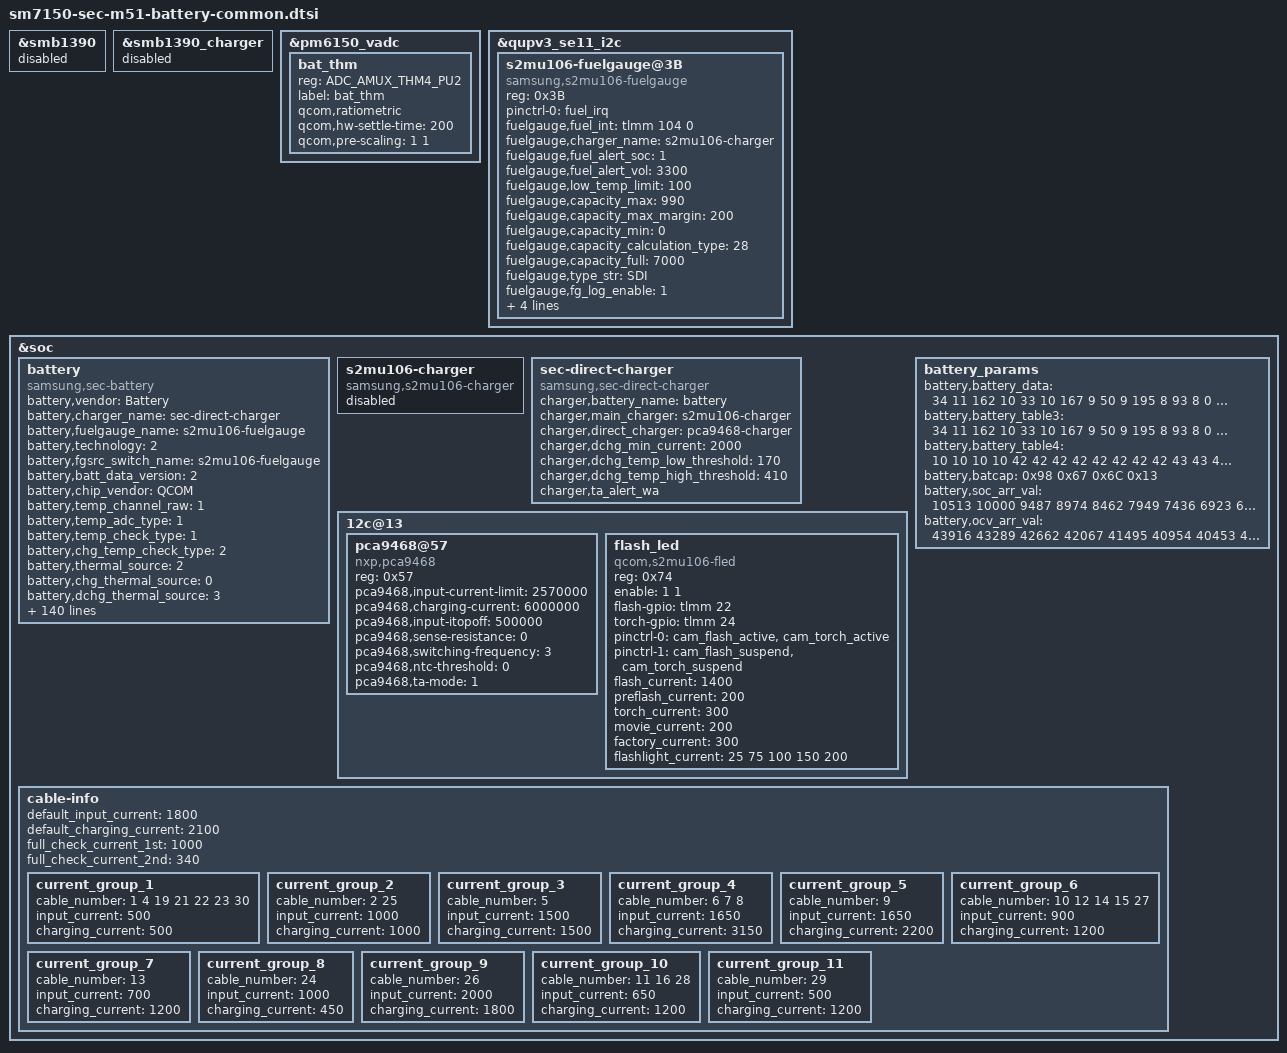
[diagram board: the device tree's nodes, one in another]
/* Copyright (c) 2019, The Linux Foundation. All rights reserved.
 *
 * This program is free software; you can redistribute it and/or modify
 * it under the terms of the GNU General Public License version 2 and
 * only version 2 as published by the Free Software Foundation.
 *
 * This program is distributed in the hope that it will be useful,
 * but WITHOUT ANY WARRANTY; without even the implied warranty of
 * MERCHANTABILITY or FITNESS FOR A PARTICULAR PURPOSE.  See the
 * GNU General Public License for more details.
 */

&smb1390 {
    status = "disabled";
};

&smb1390_charger {
    status = "disabled";
};

&pm6150_vadc {
	bat_thm {
		reg = <ADC_AMUX_THM4_PU2>;
		label = "bat_thm";
		qcom,ratiometric;
		qcom,hw-settle-time = <200>;
		qcom,pre-scaling = <1 1>;
	};
};

&qupv3_se11_i2c{
		status = "ok";

		s2mu106-fuelgauge@3B{
			compatible = "samsung,s2mu106-fuelgauge";
			reg = <0x3B>;
			pinctrl-names = "default";
			pinctrl-0 = <&fuel_irq>;
			fuelgauge,fuel_int = <&tlmm 104 0>;
			fuelgauge,charger_name = "s2mu106-charger";
			fuelgauge,fuel_alert_soc = <1>;
			fuelgauge,fuel_alert_vol = <3300>;
			fuelgauge,low_temp_limit = <100>;
			fuelgauge,capacity_max = <990>;
			fuelgauge,capacity_max_margin = <200>;
			fuelgauge,capacity_min = <0>;
			fuelgauge,capacity_calculation_type = <28>;
			fuelgauge,capacity_full = <7000>;
			fuelgauge,type_str = "SDI";
			fuelgauge,fg_log_enable = <1>;
			fuelgauge,low_voltage_limit = <3450>;
			fuelgauge,low_voltage_limit_lowtemp = <3000>;
			fuelgauge,i_socr_coeff = <80>;
			fuelgauge,low_t_compen_coeff = <180>;
		};
	};

&soc {
	battery {
		status = "okay";
		compatible = "samsung,sec-battery";
		pinctrl-names = "default";

		battery,vendor = "Battery";
		battery,charger_name = "sec-direct-charger";
		battery,fuelgauge_name = "s2mu106-fuelgauge";
		battery,technology = <2>; /* POWER_SUPPLY_TECHNOLOGY_LION */
		battery,fgsrc_switch_name = "s2mu106-fuelgauge"; /* Fuelgauge voltage source */

		battery,batt_data_version = <2>;

		battery,chip_vendor = "QCOM";
		battery,temp_channel_raw= <1>; /* BATTERY_TEMP_CHANNEL_RAW */
		battery,temp_adc_type = <1>; /* SEC_BATTERY_ADC_TYPE_AP */

		battery,temp_check_type = <1>; /* SEC_BATTERY_TEMP_CHECK_ADC */
		battery,chg_temp_check_type = <2>; /* SEC_BATTERY_TEMP_CHECK_TEMP*/

		battery,thermal_source = <2>; /* SEC_BATTERY_THERMAL_SOURCE_ADC */
		battery,chg_thermal_source = <0>; /* SEC_CHARGER_THERMAL_SOURCE_FG */

		battery,dchg_thermal_source = <3>; /* SEC_BATTERY_THERMAL_SOURCE_CHG_ADC */
		battery,polling_time = <10 30 30 30 3600>;
		

		battery,temp_table_adc = <
					1998 2411 2824 3310 3882 4543 5384 6302 7337 8485
					9728 11153 12702 14344 16061 17803 19417 20947 22363 23642
					24732 25654 26427
					>;
		battery,temp_table_data = <
					900 850 800 750 700 650 600 550	500 450
					400 350 300	250 200 150 100 50 0 (-50)
					(-100) (-150) (-200)
					>;

		battery,inbat_voltage = <1>;

		battery,inbat_voltage_table_adc = <
					2820 2795 2767 2737 2706 2686 2659 2630 2602 2574
					2544 2514 2484 2456 2432 2405 2379 2351 2320 2292
					2265 2236 2207
					>;
		battery,inbat_voltage_table_data = <
					4400 4350 4300 4250 4200 4150 4100 4050 4000 3950
					3900 3850 3800 3750 3700 3650 3600 3550 3500 3450
					3400 3350 3300
					>;
		battery,dchg_temp_table_adc = <99705 125511 151317 182988 211140 258060 308499 365976 428145 498525
					575943 663918 757758 859809 968898 1080333 1182384 1279743 1368891 1452174 1523727 1583550 1635162>;
		battery,dchg_temp_table_data = <900 850 800 750 700 650 600 550 500 450
					400 350 300 250 200 150 100 50 0 (-50) (-100) (-150) (-200)>;

		battery,adc_check_count = <5>;

		battery,cable_check_type = <4>; /* SEC_BATTERY_CABLE_CHECK_PSY */
		battery,cable_source_type = <1>; /* SEC_BATTERY_CABLE_SOURCE_EXTERNAL */
		battery,polling_type = <1>; /* SEC_BATTERY_MONITOR_ALARM */
		battery,monitor_initial_count = <0>;

		battery,pre_afc_input_current = <500>;
		battery,prepare_afc_delay = <0>;

		battery,battery_check_type = <0>; /* SEC_BATTERY_CHECK_NONE */
		battery,check_count = <0>;

		battery,ovp_uvlo_check_type = <3>; /* SEC_BATTERY_OVP_UVLO_CHGPOLLING */

		battery,temp_check_count = <1>;
		battery,temp_highlimit_threshold_event = <700>;
		battery,temp_highlimit_recovery_event = <680>;
		battery,temp_high_threshold_event = <500>;
		battery,temp_high_recovery_event = <480>;
		battery,temp_low_threshold_event = <0>;
		battery,temp_low_recovery_event = <20>;
		battery,temp_highlimit_threshold_normal = <700>;
		battery,temp_highlimit_recovery_normal = <680>;
		battery,temp_high_threshold_normal = <500>;
		battery,temp_high_recovery_normal = <480>;
		battery,temp_low_threshold_normal = <0>;
		battery,temp_low_recovery_normal = <20>;
		battery,temp_highlimit_threshold_lpm = <800>;
		battery,temp_highlimit_recovery_lpm = <750>;
		battery,temp_high_threshold_lpm = <500>;
		battery,temp_high_recovery_lpm = <480>;
		battery,temp_low_threshold_lpm = <0>;
		battery,temp_low_recovery_lpm = <20>;
		battery,wpc_high_threshold_normal = <450>;
		battery,wpc_high_recovery_normal = <400>;
		battery,wpc_low_threshold_normal = <0>;
		battery,wpc_low_recovery_normal = <50>;

		battery,full_check_type = <2>; /* SEC_BATTERY_FULLCHARGED_FG_CURRENT */
		battery,full_check_type_2nd = <2>; /* SEC_BATTERY_FULLCHARGED_FG_CURRENT */
		battery,full_check_count = <1>;
		battery,chg_gpio_full_check = <0>;
		battery,chg_polarity_full_check = <1>;

		battery,chg_heating_prevention_method = <1>; /* SEC_BATTERY_BY_CHANGING_CURRENT */
		battery,chg_high_temp = <490>;
		battery,chg_high_temp_recovery = <450>;
		battery,chg_input_limit_current = <1000>;
		battery,chg_charging_limit_current = <1800>;
		battery,dchg_input_limit_current = <1000>;
		battery,dchg_charging_limit_current = <2000>;

		battery,mix_high_temp = <420>;
		battery,mix_high_chg_temp = <500>;
		battery,mix_high_temp_recovery = <390>;

		/* SEC_BATTERY_FULL_CONDITION_SOC |
		 * SEC_BATTERY_FULL_CONDITION_NOTIMEFULL |
		 * SEC_BATTERY_FULL_CONDITION_VCELL
		 */
		battery,full_condition_type = <13>;
		battery,full_condition_soc = <93>;
		battery,full_condition_vcell = <4250>;

		battery,recharge_check_count = <1>;
		battery,recharge_condition_type = <4>; /* SEC_BATTERY_RECHARGE_CONDITION_VCELL */
		battery,recharge_condition_soc = <98>;
		battery,recharge_condition_vcell = <4310>;

		battery,charging_total_time = <14400>;
		battery,hv_charging_total_time = <10800>;
		battery,normal_charging_total_time = <18000>;
		battery,usb_charging_total_time = <36000>;
		battery,recharging_total_time = <5400>;
		battery,charging_reset_time = <0>;

		battery,chg_float_voltage = <4380>;

		battery,swelling_high_temp_block = <410>;
		battery,swelling_high_temp_recov = <390>;
		battery,swelling_wc_high_temp_recov = <390>;
		battery,swelling_low_temp_block_1st = <150>;
		battery,swelling_low_temp_recov_1st = <170>;
		battery,swelling_low_temp_block_2nd = <50>;
		battery,swelling_low_temp_recov_2nd = <70>;

		battery,swelling_low_temp_current = <1750>;
		battery,swelling_low_temp_current_2nd = <680>;
		battery,swelling_low_temp_topoff = <340>;
		battery,swelling_high_temp_current = <2600>;
		battery,swelling_high_temp_topoff = <340>;
		battery,swelling_wc_high_temp_current = <750>;	/* 0.3C */
		battery,swelling_wc_low_temp_current = <750>;	/* 0.3C */

		battery,swelling_drop_float_voltage = <4150>;
		battery,swelling_high_rechg_voltage = <4000>;
		battery,swelling_low_rechg_voltage = <4230>;

		battery,dchg_high_temp = <470>;
		battery,dchg_high_temp_recovery = <430>;

		battery,siop_event_check_type = <1>;
		battery,siop_call_cv_current = <330>;
		battery,siop_call_cc_current = <330>;

		battery,siop_input_limit_current = <1200>;
		battery,siop_charging_limit_current = <1000>;
		battery,siop_hv_input_limit_current = <700>;
		battery,siop_hv_charging_limit_current = <1000>;
		battery,input_current_by_siop_20 = <400>;

		battery,rp_current_rp1 = <500>;
		battery,rp_current_rp2 = <1500>;
		battery,rp_current_rp3 = <3000>;
		battery,rp_current_rdu_rp3 = <2100>;
		battery,rp_current_abnormal_rp3 = <1800>;

		battery,pd_charging_charge_power = <15000>;
		battery,max_charging_current = <3150>;
		battery,battery_full_capacity = <7000>;

		battery,ttf_hv_charge_current = <2550>;
		battery,ttf_dc25_charge_current = <3300>;

		battery,ttf_capacity = <5650>;
		battery,cv_data = <
					3435	832	1800
					3365	837	1770
					3298	841	1740
					3177	850	1680
					3042	858	1620
					2958	864	1560
					2834	871	1500
					2751	879	1440
					2644	886	1380
					2550	891	1320
					2467	898	1260
					2389	905	1200
					2294	910	1140
					2219	916	1080
					2124	921	1020
					2049	926	960
					1961	931	900
					1927	938	840
					1838	942	780
					1756	945	720
					1725	949	660
					1648	952	600
					1577	959	540
					1541	966	480
					1498	972	420
					1396	976	360
					1376	981	300
					1347	986	240
					1269	990	180
					1242	993	120
					1211	996	60
					1170	1000	0
					>;

		/* cycle, chg_float_voltage, recharge_condition_vcell, full_condition_vcell, full_condition_soc, step charging condition */
		battery,age_data = <0 4380 4310 4280 93
			300 4360 4290 4260 92
			400 4340 4270 4240 91
			700 4320 4250 4220 90
			1000 4270 4200 4170 89>;

		/* step charging option */
		battery,step_charging_type = <0>;

		/* direct step charging option */
		battery,dc_step_chg_type = <0xE9>;
		battery,dc_step_chg_charge_power = <22000>;
		battery,dc_step_chg_step = <3>;
		battery,dc_step_chg_cond_vol = <4090 4190 4350>; /* STEP_CHARGING_CONDITION_VOLTAGE */
		battery,dc_step_chg_cond_iin = <1950 1575 0>; /* STEP_CHARGING_CONDITION_INPUT_CURRENT */
		battery,dc_step_chg_iin_check_cnt = <3>;
		battery,dc_step_chg_cond_soc = <9 48 100>; /* STEP_CHARGING_CONDITION_SOC */
		battery,dc_step_chg_val_vfloat = <4075 4250 4380>; /* STEP_CHARGING_CONDITION_FLOAT_VOLTAGE */
		battery,dc_step_chg_val_iout = <5300 3900 3450>;

		battery,max_input_voltage = <9000>; /* mV */
		battery,max_input_current = <3000>; /* mA */

		battery,standard_curr = <3450>;
		battery,expired_time = <12600>; /* (148 + 60) ~ 210 minutes */
		battery,recharging_expired_time = <5400>;

		battery,cisd_alg_index = <7>;

		battery,cisd_max_voltage_thr = <5000>; /* battery ovp detection voltage */

		io-channels = <&pm6150_vadc ADC_AMUX_THM4_PU2>;
		io-channel-names = "adc-temp";

		battery,recovery_cable;
		battery,lowtemp_support_full_volt;
		battery,enable_water_resistance;
		battery,ta_alert_wa;
	};


	s2mu106-charger {
		status = "disable";
		compatible = "samsung,s2mu106-charger";
	};

	sec-direct-charger {
			status = "okay";
			compatible = "samsung,sec-direct-charger";

			charger,battery_name = "battery";
			charger,main_charger = "s2mu106-charger";
			charger,direct_charger = "pca9468-charger";

			charger,dchg_min_current = <2000>;
			charger,dchg_temp_low_threshold = <170>;
			charger,dchg_temp_high_threshold = <410>;
			charger,ta_alert_wa;
		};

	12c@13 {
		pca9468@57 {
			compatible = "nxp,pca9468";
			reg = <0x57>;
			pca9468,input-current-limit = <2570000>; /* 2.57A */
			pca9468,charging-current = <6000000>; /* 6A */
			pca9468,input-itopoff = <500000>; /* 500mA */
			pca9468,sense-resistance = <0>; /* 5mOhm */
			pca9468,switching-frequency = <3>; /* 980KHz */
			pca9468,ntc-threshold = <0>; /* disable */
			pca9468,ta-mode = <1>; /* 2:1 charging mode */
		};

		flash_led {
			reg = <0x74>;
			compatible = "qcom,s2mu106-fled";
			enable = <1 1>;
			flash-gpio = <&tlmm 22 0>;
			torch-gpio = <&tlmm 24 0>;
			pinctrl-names = "fled_default", "fled_suspend";
			pinctrl-0 = <&cam_flash_active &cam_torch_active>;
			pinctrl-1 = <&cam_flash_suspend &cam_torch_suspend>;
			flash_current = <1400>;
			preflash_current = <200>;
			torch_current = <300>;
			movie_current = <200>;
			factory_current = <300>;
			flashlight_current = <25 75 100 150 200>;
			status = "okay";
		};
	};

battery_params {
		battery,battery_data =
			<
			/***** battery data for 4.38 *****/
			/* battery,battery_table3 */
			34 11 162 10 33 10 167 9 50 9
			195 8 93 8 0 8 175 7 96 7
			242 6 182 6 139 6 106 6 81 6
			58 6 21 6 237 5 174 5 135 5
			246 4 191 2 105 8 0 8 151 7
			46 7 197 6 92 6 243 5 138 5
			33 5 184 4 79 4 230 3 125 3
			20 3 171 2 66 2 217 1 112 1
			7 1 158 0 53 0 243 15


			/* battery,battery_table4 */
			10 10 10 10 42 42 42 42 42 42
			42 42 43 43 43 43 43 44 44 45
			48 154


			/* battery,batcap */
			0x98 0x67 0x6C 0x13 /* [0x0E] [0x0F] [0x10] [0x11] */
			/* battery,accum */ 
			0x00 0x08 /* [0x44] [0x45] */

			/* battery,soc_arr_val */
			10513 10000 9487 8974 8462 7949 7436 6923 6410 5897
			5385 4872 4359 3846 3333 2821 2308 1795 1282 769
			256 (-63)

			/* battery,ocv_arr_val */
			43916 43289 42662 42067 41495 40954 40453 40001 39604 39221
			38681 38389 38179 38019 37894 37784 37604 37409 37099 36907
			36201 33433

			/* battery,tunning */
			0x00

			/***** battery data for 4.36 *****/
			/* battery,battery_table3 */
			34 11 162 10 33 10 167 9 50 9
			195 8 93 8 0 8 175 7 96 7
			242 6 182 6 139 6 106 6 81 6
			58 6 21 6 237 5 174 5 135 5
			246 4 191 2 131 8 25 8 175 7
			68 7 218 6 112 6 5 6 155 5
			48 5 198 4 92 4 241 3 135 3
			29 3 178 2 72 2 221 1 115 1
			9 1 158 0 52 0 242 15

			/* battery,battery_table4 */
			10 10 10 10 42 42 42 42 42 42
			42 42 43 43 43 43 43 44 44 45
			48 154


			/* battery,batcap */
			0x48 0x66 0x2D 0x13 /* [0x0E] [0x0F] [0x10] [0x11] */
			/* battery,accum */ 
			0x00 0x08 /* [0x44] [0x45] */

			/* battery,soc_arr_val */
			10642 10122 9603 9083 8564 8045 7525 7006 6487 5967
			5448 4928 4409 3890 3370 2851 2331 1812 1293 773
			254 (-69)
			
			/* battery,ocv_arr_val */
			43916 43289 42662 42067 41495 40954 40453 40001 39604 39221
			38681 38389 38179 38019 37894 37784 37604 37409 37099 36907
			36201 33433

			/* battery,tunning */
			0x00

			/***** battery data for 4.34 *****/
			/* battery,battery_table3 */
			34 11 162 10 33 10 167 9 50 9
			195 8 93 8 0 8 175 7 96 7
			242 6 182 6 139 6 106 6 81 6
			58 6 21 6 237 5 174 5 135 5
			246 4 191 2 169 8 60 8 208 7
			100 7 248 6 140 6 32 6 179 5
			71 5 219 4 111 4 3 4 150 3
			42 3 190 2 82 2 230 1 121 1
			13 1 161 0 53 0 242 15

			/* battery,battery_table4 */
			10 10 10 10 42 42 42 42 42 42
			42 42 43 43 43 43 43 44 44 45
			48 154

			/* battery,batcap */
			0x90 0x64 0xDB 0x12 /* [0x0E] [0x0F] [0x10] [0x11] */
			/* battery,accum */
			0x00 0x8 /* [0x44] [0x45] */

			/* battery,soc_arr_val */
			10824 10295 9767 9239 8711 8182 7654 7126 6597 6069
			5541 5013 4484 3956 3428 2900 2371 1843 1315 787
			258 (-70)

			
			/* battery,ocv_arr_val */
			43916 43289 42662 42067 41495 40954 40453 40001 39604 39221
			38681 38389 38179 38019 37894 37784 37604 37409 37099 36907
			36201 33433 

			/* battery,tunning */
			0x00

			/***** battery data for 4.32 *****/
			/* battery,battery_table3 */
			34 11 162 10 33 10 167 9 50 9
			195 8 93 8 0 8 175 7 96 7
			242 6 182 6 139 6 106 6 81 6
			58 6 21 6 237 5 174 5 135 5
			246 4 191 2 211 8 101 8 246 7
			136 7 26 7 172 6 61 6 207 5
			97 5 243 4 132 4 22 4 168 3
			58 3 203 2 93 2 239 1 129 1
			18 1 164 0 54 0 241 15

			/* battery,battery_table4 */
			10 10 10 10 42 42 42 42 42 42
			42 42 43 43 43 43 43 44 44 45
			48 154

			/* battery,batcap */
			0xB0 0x62 0x81 0x12 /* [0x0E] [0x0F] [0x10] [0x11] */
			/* battery,accum */
			0x00 0x8 /* [0x44] [0x45] */

			/* battery,soc_arr_val */
			11029 10491 9953 9414 8876 8338 7800 7261 6723 6185
			5646 5108 4570 4031 3493 2955 2416 1878 1340 801
			263 (-72)

			
			/* battery,ocv_arr_val */
			43916 43289 42662 42067 41495 40954 40453 40001 39604 39221
			38681 38389 38179 38019 37894 37784 37604 37409 37099 36907
			36201 33433 

			/* battery,tunning */
			0x00

			/***** battery data for 4.27 *****/
			/* battery,battery_table3 */
			34 11 162 10 33 10 167 9 50 9
			195 8 93 8 0 8 175 7 96 7
			242 6 182 6 139 6 106 6 81 6
			58 6 21 6 237 5 174 5 135 5
			246 4 191 2 56 9 197 8 81 8
			222 7 107 7 248 6 133 6 18 6
			158 5 43 5 184 4 69 4 210 3
			95 3 235 2 120 2 5 2 146 1
			31 1 171 0 56 0 241 15

			/* battery,battery_table4 */
			10 10 10 10 42 42 42 42 42 42
			42 42 43 43 43 43 43 44 44 45
			48 154

			/* battery,batcap */
			0x74 0x5E 0xB5 0x11 /* [0x0E] [0x0F] [0x10] [0x11] */
			/* battery,accum */
			0x00 0x8 /* [0x44] [0x45] */

			/* battery,soc_arr_val */
			11522 10960 10397 9835 9273 8710 8148 7586 7023 6461
			5899 5336 4774 4211 3649 3087 2524 1962 1400 837
			275 (-75)
			
			/* battery,ocv_arr_val */
			43916 43289 42662 42067 41495 40954 40453 40001 39604 39221
			38681 38389 38179 38019 37894 37784 37604 37409 37099 36907
			36201 33433

			/* battery,tunning */
			0x00
			>;

	battery,battery_table3 = <
			34 11 162 10 33 10 167 9 50 9
			195 8 93 8 0 8 175 7 96 7
			242 6 182 6 139 6 106 6 81 6
			58 6 21 6 237 5 174 5 135 5
			246 4 191 2 105 8 0 8 151 7
			46 7 197 6 92 6 243 5 138 5
			33 5 184 4 79 4 230 3 125 3
			20 3 171 2 66 2 217 1 112 1
			7 1 158 0 53 0 243 15
			>;

	battery,battery_table4 = <
			10 10 10 10 42 42 42 42 42 42
			42 42 43 43 43 43 43 44 44 45
			48 154
			>;

	battery,batcap = <0x98 0x67 0x6C 0x13>; /* [0x0E] [0x0F] [0x10] [0x11] */

	battery,soc_arr_val = <
			10513 10000 9487 8974 8462 7949 7436 6923 6410 5897
			5385 4872 4359 3846 3333 2821 2308 1795 1282 769
			256 (-63)
			>;
			
	battery,ocv_arr_val = <
			43916 43289 42662 42067 41495 40954 40453 40001 39604 39221
			38681 38389 38179 38019 37894 37784 37604 37409 37099 36907
			36201 33433
			>;
			
		};

/* sec_battery_cable
 *   0	UNKNOWN,
 *   1	NONE,
 *   2	PREPARE_TA,
 *   3	TA,
 *   4	USB,
 *   5	USB_CDP,
 *   6	9V_TA,
 *   7	9V_ERR,
 *   8	9V_UNKNOWN,
 *   9	12V_TA,
 *  10	WIRELESS,
 *  11	HV_WIRELESS,
 *  12	PMA_WIRELESS,
 *  13	WIRELESS_PACK,
 *  14	WIRELESS_PACK_TA,
 *  15	WIRELESS_STAND,
 *  16	WIRELESS_HV_STAND,
 *  17	QC20,
 *  18	QC30,
 *  19	PDIC,
 *  20	UARTOFF,
 *  21	OTG,
 *  22	LAN_HUB,
 *  23	POWER_SHARING,
 *  24	HMT_CONNECTED,
 *  25	HMT_CHARGE,
 *  26	HV_TA_CHG_LIMIT,
 *  27	WIRELESS_VEHICLE,
 *  28	WIRELESS_HV_VEHICLE,
 *  29	PREPARE_WIRELESS_HV,
 *  30	TIMEOUT,
 *  31	SMART_OTG,
 *  32	SMART_NOTG,
 *  33	WIRELESS_TX,
 *  34	WIRELESS_HV_20,
 *  35	WIRELESS_HV_20_LIMIT,
 *  36	WIRELESS_FAKE,
 *  37	WIRELESS_HV_20_PREPARE,
 *  38	PDIC_APDO,
 *  39	POGO,
 */
 
	cable-info {
		default_input_current = <1800>;
		default_charging_current = <2100>;
		full_check_current_1st = <1000>;
		full_check_current_2nd = <340>;

		current_group_1 {
			cable_number = <1 4 19 21 22 23 30>;
			input_current = <500>;
			charging_current = <500>;
		};

		current_group_2 {
			cable_number = <2 25>;
			input_current = <1000>;
			charging_current = <1000>;
		};

		current_group_3 {
			cable_number = <5>;
			input_current = <1500>;
			charging_current = <1500>;
		};

		current_group_4 {
			cable_number = <6 7 8>;
			input_current = <1650>;
			charging_current = <3150>;
		};

		current_group_5 {
			cable_number = <9>;
			input_current = <1650>;
			charging_current = <2200>;
		};

		current_group_6 {
			cable_number = <10 12 14 15 27>;
			input_current = <900>;
			charging_current = <1200>;
		};

		current_group_7 {
			cable_number = <13>;
			input_current = <700>;
			charging_current = <1200>;
		};

		current_group_8 {
			cable_number = <24>;
			input_current = <1000>;
			charging_current = <450>;
		};

		current_group_9 {
			cable_number = <26>;
			input_current = <2000>;
			charging_current = <1800>;
		};

		current_group_10 {
			cable_number = <11 16 28>;
			input_current = <650>;
			charging_current = <1200>;
		};

		current_group_11 {
			cable_number = <29>;
			input_current = <500>;
			charging_current = <1200>;
		};
	};
};
